# STM32U385 register map
File version: 1.0
CPU: CM33 r0p1, little endian, MPU, FPU, 4 interrupt priority bits
Registers are 32-bit, read-write, reset 0x0 unless marked. A register's access mark holds for its fields unless they carry their own. Offsets are from the block's base; [hi:lo] are bit positions; {n}, {i} and the like mark numbered series.

## USBSRAM — USBSRAM Address block
Base 0x40016400
Same registers: SEC_USBSRAM 0x50016400
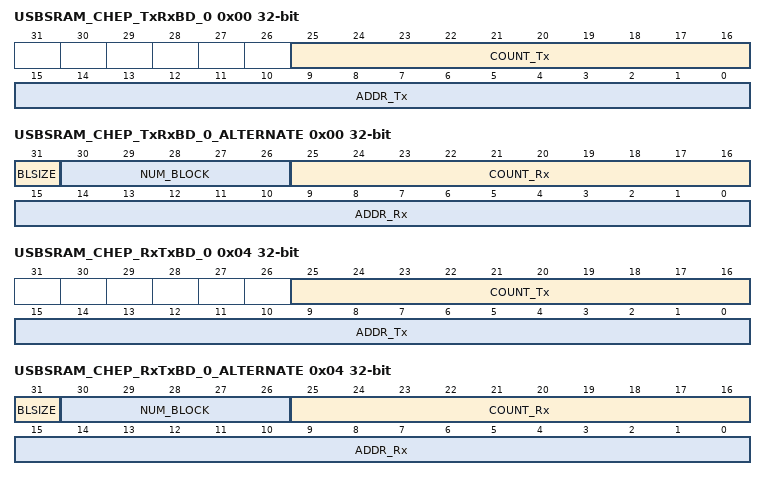
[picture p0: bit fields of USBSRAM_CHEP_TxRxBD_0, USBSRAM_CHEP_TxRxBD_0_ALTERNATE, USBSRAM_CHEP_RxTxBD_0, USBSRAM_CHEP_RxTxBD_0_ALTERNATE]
0x00 USBSRAM_CHEP_TxRxBD_0 reset not defined — Channel/endpoint transmit buffer descriptor 0
  [25:16] COUNT_Tx — These bits contain the number of bytes to be transmitted by the endpoint/channel associated with the USB_CHEP0R register at the next IN token addressed to it.
  [15:0] ADDR_Tx — These bits point to the starting address of the packet buffer containing data to be transmitted by the endpoint/channel
0x00 USBSRAM_CHEP_TxRxBD_0_ALTERNATE access per field reset not defined (alternate view of USBSRAM_CHEP_TxRxBD_0) — Channel/endpoint transmit buffer descriptor 0
  [31] BLSIZE rw — This bit selects the size of memory block used to define the allocated buffer area. - If BLSIZE = 0, the memory block is 2-byte large, which is the minimum block allowed in a half-word wide memory. With this block size the allocated buffer size ranges from 2 to 62 bytes. - If BLSIZE = 1, the memory block is 32-byte large, which permits to reach the maximum packet length defined by USB specifications. With this block size the allocated buffer size theoretically ranges from 32 to 1024 bytes, which is the longest packet size allowed by USB standard specifications. However, the applicable size is limited by the available buffer memory.
  [30:26] NUM_BLOCK rw — These bits define the number of memory blocks allocated to this packet buffer. The actual amount of allocated memory depends on the BLSIZE value as illustrated in less than xe7 []/>.
  [25:16] COUNT_Rx ro — These bits contain the number of bytes received by the endpoint/channel
  [15:0] ADDR_Rx rw — These bits point to the starting address of the packet buffer
0x04 USBSRAM_CHEP_RxTxBD_0 reset not defined — Channel/endpoint transmit buffer descriptor 0
  [25:16] COUNT_Tx — These bits contain the number of bytes to be transmitted by the endpoint/channel associated with the USB_CHEPnR register at the next IN token addressed to it.
  [15:0] ADDR_Tx — These bits point to the starting address of the packet buffer containing data to be transmitted by the endpoint/channel associated with the USB_CHEP0R register at the next IN token addressed to it.
0x04 USBSRAM_CHEP_RxTxBD_0_ALTERNATE access per field reset not defined (alternate view of USBSRAM_CHEP_RxTxBD_0) — Channel/endpoint transmit buffer descriptor 0
  [31] BLSIZE rw — This bit selects the size of memory block used to define the allocated buffer area. - If BLSIZE = 0, the memory block is 2-byte large, which is the minimum block allowed in a half-word wide memory. With this block size the allocated buffer size ranges from 2 to 62 bytes. - If BLSIZE = 1, the memory block is 32-byte large, which permits to reach the maximum packet length defined by USB specifications. With this block size the allocated buffer size theoretically ranges from 32 to 1024 bytes, which is the longest packet size allowed by USB standard specifications. However, the applicable size is limited by the available buffer memory.
  [30:26] NUM_BLOCK rw — These bits define the number of memory blocks allocated to this packet buffer. The actual amount of allocated memory depends on the BLSIZE value as illustrated in less than xe7 []/>.
  [25:16] COUNT_Rx ro — These bits contain the number of bytes received by the endpoint/channel associated with the USB_CHEPnR register during the last OUT/SETUP transaction addressed to it.
  [15:0] ADDR_Rx rw — These bits point to the starting address of the packet buffer, which contains the data received by the endpoint/channel associated with the USB_CHEP0R register at the next OUT/SETUP token addressed to it.
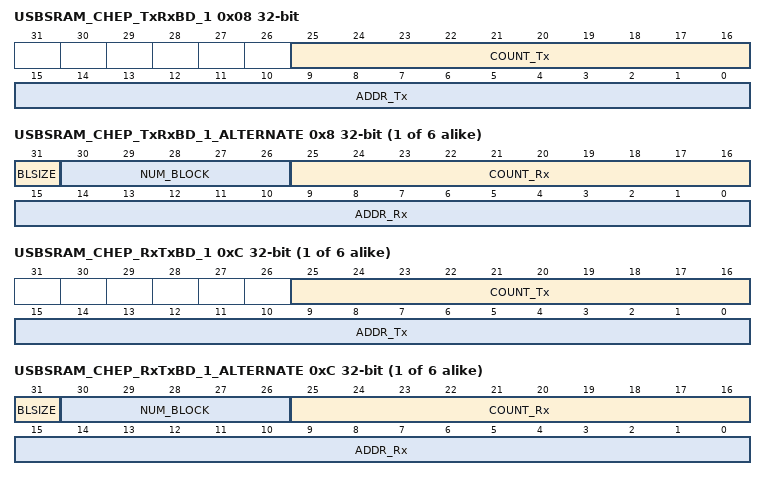
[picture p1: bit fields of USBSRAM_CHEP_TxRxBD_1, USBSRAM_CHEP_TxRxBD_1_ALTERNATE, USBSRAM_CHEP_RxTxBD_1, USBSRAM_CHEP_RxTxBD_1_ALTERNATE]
0x08 USBSRAM_CHEP_TxRxBD_1 reset not defined — Channel/endpoint transmit buffer descriptor 1
  [25:16] COUNT_Tx — These bits contain the number of bytes to be transmitted by the endpoint/channel associated with the USB_CHEP1R register at the next IN token addressed to it.
  [15:0] ADDR_Tx — These bits point to the starting address of the packet buffer containing data to be transmitted by the endpoint/channel associated with the USB_CHEP1R register at the next IN token addressed to it.
{0x0+8i} USBSRAM_CHEP_TxRxBD_{i}_ALTERNATE access per field reset not defined (alternate view of USBSRAM_CHEP_TxRxBD_{i}) (i=1..6) — Channel/endpoint transmit buffer descriptor {i}
  [31] BLSIZE rw — This bit selects the size of memory block used to define the allocated buffer area. - If BLSIZE = 0, the memory block is 2-byte large, which is the minimum block allowed in a half-word wide memory. With this block size the allocated buffer size ranges from 2 to 62 bytes. - If BLSIZE = 1, the memory block is 32-byte large, which permits to reach the maximum packet length defined by USB specifications. With this block size the allocated buffer size theoretically ranges from 32 to 1024 bytes, which is the longest packet size allowed by USB standard specifications. However, the applicable size is limited by the available buffer memory.
  [30:26] NUM_BLOCK rw — These bits define the number of memory blocks allocated to this packet buffer. The actual amount of allocated memory depends on the BLSIZE value as illustrated in less than xe7 []/>.
  [25:16] COUNT_Rx ro — These bits contain the number of bytes received by the endpoint/channel associated with the USB_CHEP{i}R register during the last OUT/SETUP transaction addressed to it.
  [15:0] ADDR_Rx rw — These bits point to the starting address of the packet buffer, which contains the data received by the endpoint/channel associated with the USB_CHEP{i}R register at the next OUT/SETUP token addressed to it. Bits 1 and 0 must always be written as '00 ' since packet memory is word wide and all packet buffers must be word aligned. Note: This table location is used to store two different values, both required during packet reception. The most significant bits contains the definition of allocated buffer size, to allow buffer overflow detection, while the least significant part of this location is written back by the USB peripheral at the end of reception to give the actual number of received bytes. Due to the restrictions on the number of available bits, buffer size is represented using the number of allocated memory blocks, where block size can be selected to choose the trade-off between fine-granularity/small-buffer and coarse-granularity/large-buffer. The size of allocated buffer is a part of the endpoint/channel descriptor and it is normally defined during the enumeration process according to its maxPacketSize parameter value (see 'Universal Serial Bus Specification ').
{0x4+8i} USBSRAM_CHEP_RxTxBD_{i} reset not defined (i=1..6) — Channel/endpoint transmit buffer descriptor {i}
  [25:16] COUNT_Tx — These bits contain the number of bytes to be transmitted by the endpoint/channel associated with the USB_CHEPnR register at the next IN token addressed to it.
  [15:0] ADDR_Tx — These bits point to the starting address of the packet buffer containing data to be transmitted by the endpoint/channel associated with the USB_CHEP{i}R register at the next IN token addressed to it. Bits 1 and 0 must always be written as '00 ' since packet memory is word wide and all packet buffers must be word aligned.
{0x4+8i} USBSRAM_CHEP_RxTxBD_{i}_ALTERNATE access per field reset not defined (alternate view of USBSRAM_CHEP_RxTxBD_{i}) (i=1..6) — Channel/endpoint transmit buffer descriptor {i}
  [31] BLSIZE rw — This bit selects the size of memory block used to define the allocated buffer area. - If BLSIZE = 0, the memory block is 2-byte large, which is the minimum block allowed in a half-word wide memory. With this block size the allocated buffer size ranges from 2 to 62 bytes. - If BLSIZE = 1, the memory block is 32-byte large, which permits to reach the maximum packet length defined by USB specifications. With this block size the allocated buffer size theoretically ranges from 32 to 1024 bytes, which is the longest packet size allowed by USB standard specifications. However, the applicable size is limited by the available buffer memory.
  [30:26] NUM_BLOCK rw — These bits define the number of memory blocks allocated to this packet buffer. The actual amount of allocated memory depends on the BLSIZE value as illustrated in less than xe7 []/>.
  [25:16] COUNT_Rx ro — These bits contain the number of bytes received by the endpoint/channel associated with the USB_CHEPnR register during the last OUT/SETUP transaction addressed to it.
  [15:0] ADDR_Rx rw — These bits point to the starting address of the packet buffer, which contains the data received by the endpoint/channel associated with the USB_CHEP{i}R register at the next OUT/SETUP token addressed to it. Bits 1 and 0 must always be written as '00 ' since packet memory is word wide and all packet buffers must be word aligned. Note: This table location is used to store two different values, both required during packet reception. The most significant bits contains the definition of allocated buffer size, to allow buffer overflow detection, while the least significant part of this location is written back by the USB peripheral at the end of reception to give the actual number of received bytes. Due to the restrictions on the number of available bits, buffer size is represented using the number of allocated memory blocks, where block size can be selected to choose the trade-off between fine-granularity/small-buffer and coarse-granularity/large-buffer. The size of allocated buffer is a part of the endpoint/channel descriptor and it is normally defined during the enumeration process according to its maxPacketSize parameter value (see 'Universal Serial Bus Specification ').
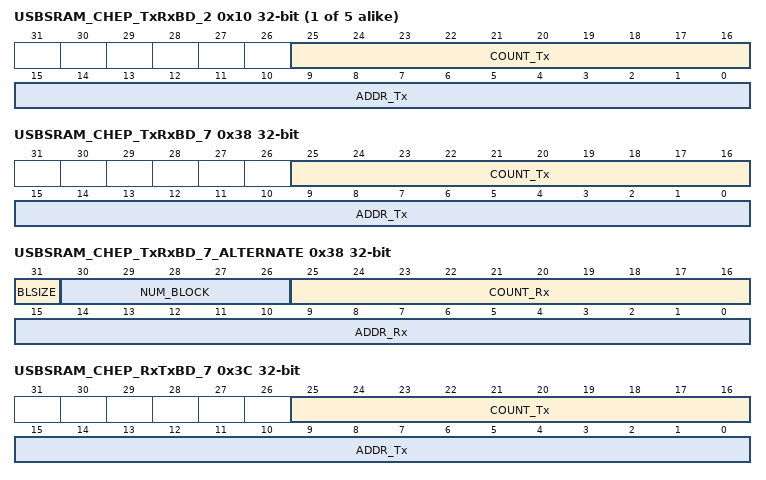
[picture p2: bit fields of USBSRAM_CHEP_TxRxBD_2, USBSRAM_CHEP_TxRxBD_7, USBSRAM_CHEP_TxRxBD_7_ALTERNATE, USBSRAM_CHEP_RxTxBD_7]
{0x0+8i} USBSRAM_CHEP_TxRxBD_{i} reset not defined (i=2..6) — Channel/endpoint transmit buffer descriptor {i}
  [25:16] COUNT_Tx — These bits contain the number of bytes to be transmitted by the endpoint/channel associated with the USB_CHEP{i}R register at the next IN token addressed to it.
  [15:0] ADDR_Tx — These bits point to the starting address of the packet buffer containing data to be transmitted by the endpoint/channel associated with the USB_CHEP{i}R register at the next IN token addressed to it. Bits 1 and 0 must always be written as '00 ' since packet memory is word wide and all packet buffers must be word aligned.
0x38 USBSRAM_CHEP_TxRxBD_7 reset not defined — Channel/endpoint transmit buffer descriptor 7
  [25:16] COUNT_Tx — These bits contain the number of bytes to be transmitted by the endpoint/channel associated with the USB_CHEP7R register at the next IN token addressed to it.
  [15:0] ADDR_Tx — These bits point to the starting address of the packet buffer
0x38 USBSRAM_CHEP_TxRxBD_7_ALTERNATE access per field reset not defined (alternate view of USBSRAM_CHEP_TxRxBD_7) — Channel/endpoint transmit buffer descriptor 7
  [31] BLSIZE rw — This bit selects the size of memory block used to define the allocated buffer area. - If BLSIZE = 0, the memory block is 2-byte large, which is the minimum block allowed in a half-word wide memory. With this block size the allocated buffer size ranges from 2 to 62 bytes. - If BLSIZE = 1, the memory block is 32-byte large, which permits to reach the maximum packet length defined by USB specifications. With this block size the allocated buffer size theoretically ranges from 32 to 1024 bytes, which is the longest packet size allowed by USB standard specifications. However, the applicable size is limited by the available buffer memory.
  [30:26] NUM_BLOCK rw — These bits define the number of memory blocks allocated to this packet buffer. The actual amount of allocated memory depends on the BLSIZE value as illustrated in less than xe7 []/>.
  [25:16] COUNT_Rx ro — These bits contain the number of bytes received by the endpoint/channel associated with the USB_CHEP7R register during the last OUT/SETUP transaction addressed to it.
  [15:0] ADDR_Rx rw — These bits point to the starting address of the packet buffer
0x3C USBSRAM_CHEP_RxTxBD_7 reset not defined — Channel/endpoint transmit buffer descriptor 7
  [25:16] COUNT_Tx — These bits contain the number of bytes to be transmitted by the endpoint/channel associated with the USB_CHEPnR register at the next IN token addressed to it.
  [15:0] ADDR_Tx — These bits point to the starting address of the packet buffer
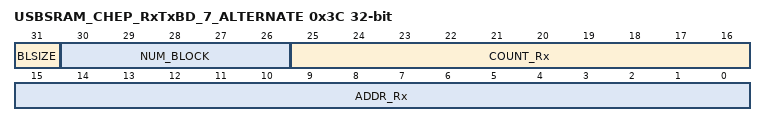
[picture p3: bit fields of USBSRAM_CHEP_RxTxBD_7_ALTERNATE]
0x3C USBSRAM_CHEP_RxTxBD_7_ALTERNATE access per field reset not defined (alternate view of USBSRAM_CHEP_RxTxBD_7) — Channel/endpoint transmit buffer descriptor 7
  [31] BLSIZE rw — This bit selects the size of memory block used to define the allocated buffer area. - If BLSIZE = 0, the memory block is 2-byte large, which is the minimum block allowed in a half-word wide memory. With this block size the allocated buffer size ranges from 2 to 62 bytes. - If BLSIZE = 1, the memory block is 32-byte large, which permits to reach the maximum packet length defined by USB specifications. With this block size the allocated buffer size theoretically ranges from 32 to 1024 bytes, which is the longest packet size allowed by USB standard specifications. However, the applicable size is limited by the available buffer memory.
  [30:26] NUM_BLOCK rw — These bits define the number of memory blocks allocated to this packet buffer. The actual amount of allocated memory depends on the BLSIZE value as illustrated in less than xe7 []/>.
  [25:16] COUNT_Rx ro — These bits contain the number of bytes received by the endpoint/channel associated with the USB_CHEPnR register during the last OUT/SETUP transaction addressed to it.
  [15:0] ADDR_Rx rw — These bits point to the starting address of the packet buffer
